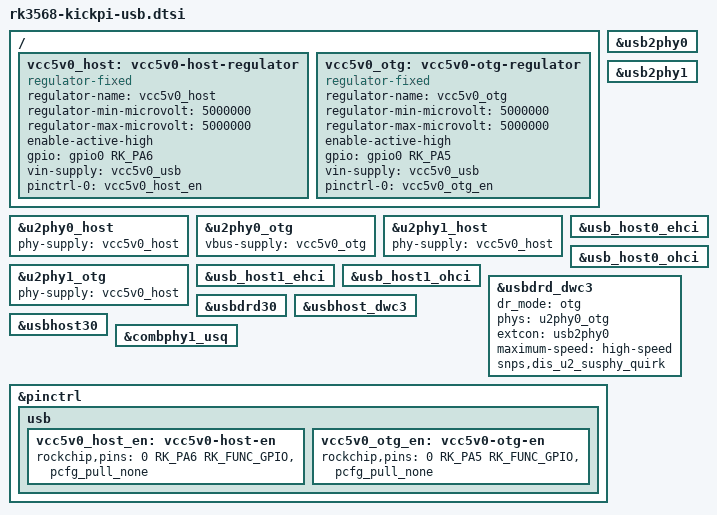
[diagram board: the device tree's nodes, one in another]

/ {
	vcc5v0_host: vcc5v0-host-regulator {
		compatible = "regulator-fixed";
		regulator-name = "vcc5v0_host";
		// regulator-boot-on;
		// regulator-always-on;
		regulator-min-microvolt = <5000000>;
		regulator-max-microvolt = <5000000>;
		enable-active-high;
		gpio = <&gpio0 RK_PA6 GPIO_ACTIVE_HIGH>;
		vin-supply = <&vcc5v0_usb>;
		pinctrl-names = "default";
		pinctrl-0 = <&vcc5v0_host_en>;
	};

	vcc5v0_otg: vcc5v0-otg-regulator {
		compatible = "regulator-fixed";
		regulator-name = "vcc5v0_otg";
		regulator-min-microvolt = <5000000>;
		regulator-max-microvolt = <5000000>;
		enable-active-high;
		gpio = <&gpio0 RK_PA5 GPIO_ACTIVE_HIGH>;
		vin-supply = <&vcc5v0_usb>;
		pinctrl-names = "default";
		pinctrl-0 = <&vcc5v0_otg_en>;
	};
};

// USB2.0 PHY0 OTG
&usb2phy0 {
	status = "okay";
};

&u2phy0_host {
	phy-supply = <&vcc5v0_host>;
	status = "okay";
};

&u2phy0_otg {
	vbus-supply = <&vcc5v0_otg>;
	status = "okay";
};

// USB2.0 PHY1 HOST
&usb2phy1 {
	status = "okay";
};

&u2phy1_host {
	phy-supply = <&vcc5v0_host>;
	status = "okay";
};

&u2phy1_otg {
	phy-supply = <&vcc5v0_host>;
	status = "okay";
};

// USB2.0 Controller HOST X2
&usb_host0_ehci {
	status = "okay";
};

&usb_host0_ohci {
	status = "okay";
};

&usb_host1_ehci {
	status = "okay";
};

&usb_host1_ohci {
	status = "okay";
};

// USB3.0 Controller OTG
&usbdrd_dwc3 {
	dr_mode = "otg";
	status = "okay";

	// USB2.0 OTG
	phys = <&u2phy0_otg>;
	phy-names = "usb2-phy";
	extcon = <&usb2phy0>;
	maximum-speed = "high-speed";
	snps,dis_u2_susphy_quirk;
};

&usbdrd30 {
	status = "okay";
};

// USB3.0 Controller HOST
&usbhost_dwc3 {
	status = "okay";
};

&usbhost30 {
	status = "okay";
};

// Multi-PHY0 to USB3.0 HOST
&combphy1_usq {
	status = "okay";
};

&pinctrl {
	usb {
		vcc5v0_host_en: vcc5v0-host-en {
			rockchip,pins = <0 RK_PA6 RK_FUNC_GPIO &pcfg_pull_none>;
		};

		vcc5v0_otg_en: vcc5v0-otg-en {
			rockchip,pins = <0 RK_PA5 RK_FUNC_GPIO &pcfg_pull_none>;
		};
	};
};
